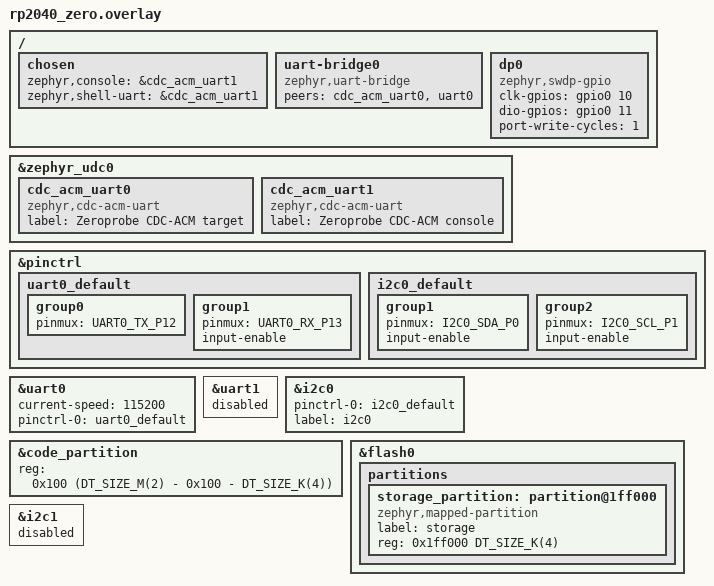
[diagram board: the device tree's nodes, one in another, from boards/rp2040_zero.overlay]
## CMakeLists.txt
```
# Copyright (c) 2023 Nordic Semiconductor ASA
# SPDX-License-Identifier: Apache-2.0
set(BOARD "rp2040_zero/rp2040")

cmake_minimum_required(VERSION 3.20.0)
find_package(Zephyr REQUIRED HINTS $ENV{ZEPHYR_BASE})
project(dap)

#include(${ZEPHYR_BASE}/samples/subsys/usb/common/common.cmake)
include_directories(include)
FILE(GLOB app_sources src/*.c)
target_sources(app PRIVATE ${app_sources})
# Hook USB transfer completions to drive the activity LED
target_link_options(app PUBLIC -Wl,--wrap=usbd_class_handle_xfer)
```

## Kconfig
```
# Copyright (c) 2026 Iacopo Moles
# SPDX-License-Identifier: Apache-2.0

menu "Zeroprobe options"
	depends on USB_DEVICE_STACK_NEXT

config APP_USBD_MANUFACTURER
	string "USB device sample manufacturer string"
	default "Zephyr Project"
	help
	  USB device sample manufacturer string.

config APP_USBD_PRODUCT
	string "USB device sample product string"
	default "Zeroprobe"
	help
	  USB device sample product stringa.

config APP_USBD_VID
	hex "USB device sample Vendor ID"
	default 0x2fe3
	help
	  USB device sample Vendor ID. The default id (0x2fe3) is associated to
	  Zephyr Project, you must use your own VID for samples and applications
	  outside of Zephyr Project.

config APP_USBD_PID
	hex "USB device sample Product ID"
	default 0x2ef0
	help
	  USB device sample Product ID. You must use your own PID for samples
	  and applications outside of Zephyr Project.

config APP_USBD_SELF_POWERED
	bool "USB device sample Self-powered attribute"
	default n
	help
	  Set the Self-powered attribute in the sample configuration.

config APP_USBD_REMOTE_WAKEUP
	bool "USB device sample Remote Wakeup attribute"
	help
	  Set the Remote Wakeup attribute in the sample configuration.

config APP_USBD_MAX_POWER
	int "USB device sample bMaxPower value"
	default 125
	range 0 250
	help
	  bMaxPower value in the sample configuration in 2 mA units.

config APP_USBD_20_EXTENSION_DESC
	bool "Use default USB 2.0 Extension Descriptor"
	depends on USBD_BOS_SUPPORT
	help
	  Set bcdUSB value to 0201 and use default USB 2.0 Extension Descriptor.

endmenu

menu "Zeroprobe status LED"

config APP_LED_COLOR_UNCONFIGURED
	hex "LED color when not configured by a USB host"
	default 0x200000
	range 0x000000 0xffffff
	help
	  Status LED color as 0xRRGGBB, shown at boot, after a USB bus reset,
	  or when the host deconfigures the device.

config APP_LED_COLOR_CONFIGURED
	hex "LED color when configured by a USB host"
	default 0x000020
	range 0x000000 0xffffff
	help
	  Status LED color as 0xRRGGBB, shown when the host has configured the
	  device and there is no USB traffic.

config APP_LED_COLOR_ACTIVE
	hex "LED color on USB traffic"
	default 0x002000
	range 0x000000 0xffffff
	help
	  Status LED color as 0xRRGGBB, shown while there is USB traffic on
	  any non-control endpoint.

config APP_LED_IDLE_TIMEOUT_MS
	int "USB traffic idle timeout in milliseconds"
	default 500
	range 1 60000
	help
	  Time without USB traffic before the status LED falls back from the
	  active color to the configured color.

endmenu


source "Kconfig.zephyr"
```

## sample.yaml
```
# This file is provided so that the application can be compiled using Twister,
# the Zephyr testing tool. In this file, multiple combinations can be specified,
# so that you can easily test all of them locally or in CI.
sample:
  description: Example application
  name: example-application 
common:
  build_only: true
  integration_platforms:
    - rp2040_zero
tests:
  app.default: {}
  app.debug:
    extra_overlay_confs:
      - debug.conf
```

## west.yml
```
manifest:
  remotes:
    - name: zephyrproject
      url-base: https://github.com/zephyrproject-rtos
  projects:
    - name: zephyr
      repo-path: zephyr
      remote: zephyrproject
      revision: "v4.5.0-rc3"
      clone-depth: 1
      import:
        path-prefix: external
        name-allowlist:
          - cmsis_6
          - hal_rpi_pico
```

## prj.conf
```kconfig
CONFIG_USB_DEVICE_STACK_NEXT=y
# CMSIS-DAP commands and SWD transfers run in the USB device stack thread
CONFIG_USBD_THREAD_STACK_SIZE=2048
CONFIG_UDC_RPI_PICO_STACK_SIZE=1024
CONFIG_CDC_ACM_SERIAL_INITIALIZE_AT_BOOT=n
CONFIG_APP_USBD_PRODUCT="Zeroprobe CMSIS-DAP"
CONFIG_APP_USBD_PID=0x2ef0
CONFIG_APP_USBD_20_EXTENSION_DESC=y
CONFIG_APP_USBD_SELF_POWERED=n

CONFIG_STDOUT_CONSOLE=y
CONFIG_SERIAL=y
CONFIG_UART_INTERRUPT_DRIVEN=y
CONFIG_UART_LINE_CTRL=y

CONFIG_LOG=y
CONFIG_LOG_DEFAULT_LEVEL=2

CONFIG_DAP_LOG_LEVEL_INF=y
CONFIG_DP_DRIVER_LOG_LEVEL_INF=y
CONFIG_DAP=y
CONFIG_DAP_BACKEND_USB=y
CONFIG_CMSIS_DAP_PROBE_VENDOR="Zephyr"
CONFIG_CMSIS_DAP_PROBE_NAME="CMSIS-DAP"
CONFIG_CMSIS_DAP_BOARD_VENDOR="Waveshare"
CONFIG_CMSIS_DAP_BOARD_NAME="RP2040-Zero"
# Leave empty: the probe is not tied to a target, and pyOCD/OpenOCD would
# otherwise try to use the device name as the target type
CONFIG_CMSIS_DAP_DEVICE_VENDOR=""
CONFIG_CMSIS_DAP_DEVICE_NAME=""

CONFIG_GPIO=y
CONFIG_LED_STRIP=y
# Status LED colors stored in the storage partition
CONFIG_FLASH=y
CONFIG_FLASH_MAP=y
CONFIG_CRC=y
CONFIG_I2C=y
CONFIG_SHELL=y
CONFIG_SHELL_STACK_SIZE=3072
CONFIG_I2C_SHELL=y

CONFIG_DEVICE_SHELL=y
CONFIG_DEVICE_SHELL_INIT_CMD=y
CONFIG_DATE_SHELL=n
CONFIG_DEVMEM_SHELL=n
CONFIG_APP_VERSION_SHELL=y
CONFIG_SHELL_MINIMAL=n
CONFIG_STATS=n

CONFIG_SPEED_OPTIMIZATIONS=y
CONFIG_BUILD_OUTPUT_STRIPPED=y
```

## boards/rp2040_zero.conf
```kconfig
CONFIG_USBD_CDC_ACM_LOG_LEVEL_OFF=y

# Status LED colors as 0xRRGGBB, keep values low, the WS2812 is very bright
CONFIG_APP_LED_COLOR_UNCONFIGURED=0x200000
CONFIG_APP_LED_COLOR_CONFIGURED=0x000020
CONFIG_APP_LED_COLOR_ACTIVE=0x002000
CONFIG_APP_LED_IDLE_TIMEOUT_MS=500

# RPI PICO binary info, shown by 'picotool info -a'.
CONFIG_RPI_PICO_BINARY_INFO=y
CONFIG_RPI_PICO_BINARY_INFO_OVERRIDE_PROGRAM_NAME="Zeroprobe"
CONFIG_RPI_PICO_BINARY_INFO_OVERRIDE_PROGRAM_DESCRIPTION="CMSIS-DAP debug probe for the Waveshare RP2040-Zero"
CONFIG_RPI_PICO_BINARY_INFO_OVERRIDE_PROGRAM_URL="https://github.com/icpmoles/zeroprobe"
CONFIG_RPI_PICO_BINARY_INFO_PROGRAM_VERSION_STRING=y
CONFIG_RPI_PICO_BINARY_INFO_PIN_CONFIGURATIONS=y
```

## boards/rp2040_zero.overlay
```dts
/ {
	chosen {
		zephyr,console = &cdc_acm_uart1;
		zephyr,shell-uart = &cdc_acm_uart1;
	};

	uart-bridge0 {
		compatible = "zephyr,uart-bridge";
		peers = <&cdc_acm_uart0 &uart0>;
	};

	dp0 {
		compatible = "zephyr,swdp-gpio";
		status = "okay";
		clk-gpios = <&gpio0 10 GPIO_ACTIVE_HIGH>;
		dio-gpios = <&gpio0 11 GPIO_PULL_UP>;
		port-write-cycles = <1>;
	};
};

&zephyr_udc0 {
	cdc_acm_uart0: cdc_acm_uart0 {
		compatible = "zephyr,cdc-acm-uart";
		label = "Zeroprobe CDC-ACM target";
	};

	cdc_acm_uart1: cdc_acm_uart1 {
		compatible = "zephyr,cdc-acm-uart";
		label = "Zeroprobe CDC-ACM console";
	};
};

&pinctrl {
	uart0_default: uart0_default {
		group0 {
			pinmux = <UART0_TX_P12>;
		};

		group1 {
			pinmux = <UART0_RX_P13>;
			input-enable;
		};
	};

	i2c0_default: i2c0_default {
		group1 {
			pinmux = <I2C0_SDA_P0>;
			input-enable;
		};

		group2 {
			pinmux = <I2C0_SCL_P1>;
			input-enable;
		};
	};

};

&uart0 {
	current-speed = <115200>;
	pinctrl-names = "default";
	status = "okay";
	pinctrl-0 = <&uart0_default>;
};

&uart1 {
	status = "disabled";
};

&i2c0 {
	pinctrl-0 = <&i2c0_default>;
	label = "i2c0";
};

/* Take the last flash sector from the code partition for persistent data */
&code_partition {
	reg = <0x100 (DT_SIZE_M(2) - 0x100 - DT_SIZE_K(4))>;
};

&flash0 {
	partitions {
		storage_partition: partition@1ff000 {
			compatible = "zephyr,mapped-partition";
			label = "storage";
			reg = <0x1ff000 DT_SIZE_K(4)>;
		};
	};
};

&i2c1 {
	status = "disabled";
};
```

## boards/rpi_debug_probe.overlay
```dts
/*
 * Copyright The Zephyr Project Contributors
 *
 * SPDX-License-Identifier: Apache-2.0
 */

/ {
	chosen {
		zephyr,console = &cdc_acm_uart1;
		zephyr,shell-uart = &cdc_acm_uart1;
	};

	uart-bridge0 {
		compatible = "zephyr,uart-bridge";
		peers = <&cdc_acm_uart0 &uart0>;
	};

	dp0 {
		compatible = "zephyr,swdp-gpio";
		status = "okay";
		clk-gpios = <&gpio0 10 GPIO_ACTIVE_HIGH>;
		dio-gpios = <&gpio0 11 GPIO_PULL_UP>;
		port-write-cycles = <1>;
	};
};

&zephyr_udc0 {
	cdc_acm_uart0: cdc_acm_uart0 {
		compatible = "zephyr,cdc-acm-uart";
		label = "Zephyr USB CDC-ACM target";
	};

	cdc_acm_uart1: cdc_acm_uart1 {
		compatible = "zephyr,cdc-acm-uart";
		label = "Zephyr USB CDC-ACM console";
	};
};

&pinctrl {
	uart0_default: uart0_default {
		group0 {
			pinmux = <UART0_TX_P12>;
		};

		group1 {
			pinmux = <UART0_RX_P13>;
			input-enable;
		};
	};
};

&uart0 {
	current-speed = <115200>;
	pinctrl-names = "default";
	status = "okay";
	pinctrl-0 = <&uart0_default>;
};
&uart1 {
	status = "disabled";
};
```

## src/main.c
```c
/*
 * Copyright (c) 2023 Nordic Semiconductor ASA
 * Copyright (c) 2026 Iacopo Moles
 *
 * SPDX-License-Identifier: Apache-2.0
 */

#include "usbd_impl.h"
#include "status_led.h"

#include <zephyr/kernel.h>
#include <zephyr/device.h>
#include <zephyr/sys/byteorder.h>
#include <zephyr/usb/usbd.h>
#include <zephyr/usb/bos.h>
#include <zephyr/usb/msos_desc.h>
#include <zephyr/dap/dap_link.h>
#include <zephyr/drivers/uart/uart_bridge.h>

#include <zephyr/logging/log.h>
LOG_MODULE_REGISTER(dap_sample, LOG_LEVEL_INF);

#include "webusb.h"
#include "msosv2.h"

DAP_LINK_CONTEXT_DEFINE(sample_dap_ctx, DEVICE_DT_GET_ONE(zephyr_swdp_gpio));

/* Bridges the target CDC ACM port and the target UART */
static const struct device *const uart_bridge = DEVICE_DT_GET_ONE(zephyr_uart_bridge);

/*
 * The USB device stack has no traffic notification, so intercept the
 * dispatch of completed non-control endpoint transfers to class instances.
 * Wrapped with -Wl,--wrap=usbd_class_handle_xfer, see CMakeLists.txt.
 */
int __real_usbd_class_handle_xfer(struct usbd_context *const uds_ctx,
				  struct net_buf *const buf,
				  const int err);

int __wrap_usbd_class_handle_xfer(struct usbd_context *const uds_ctx,
				  struct net_buf *const buf,
				  const int err)
{
	if (err == 0) {
		status_led_activity();
	}

	return __real_usbd_class_handle_xfer(uds_ctx, buf, err);
}

static void sample_msg_cb(struct usbd_context *const ctx, const struct usbd_msg *msg)
{
	// LOG_INF("USBD message: %s", usbd_msg_type_string(msg->type));

	/*
	 * Unconfigured, configured by the host, or active on traffic within the
	 * idle timeout, colors and timeout are set from the 'led' shell command.
	 * Other messages, e.g. CDC ACM line state, leave the LED unchanged.
	 */
	switch (msg->type) {
	case USBD_MSG_RESET:
	case USBD_MSG_VBUS_REMOVED:
		status_led_set(STATUS_LED_UNCONFIGURED);
		break;
	case USBD_MSG_CONFIGURATION:
		/* Status is the configuration value, 0 means unconfigured */
		status_led_set(msg->status ? STATUS_LED_CONFIGURED : STATUS_LED_UNCONFIGURED);
		break;
	default:
		break;
	}

	if (usbd_can_detect_vbus(ctx)) {
		if (msg->type == USBD_MSG_VBUS_READY) {
			if (usbd_enable(ctx)) {
				LOG_ERR("Failed to enable device support");
			}
		}

		if (msg->type == USBD_MSG_VBUS_REMOVED) {
			if (usbd_disable(ctx)) {
				LOG_ERR("Failed to disable device support");
			}
		}
	}

	/*
	 * Apply the baud rate and framing chosen on the host to the target UART,
	 * the bridge does not do it on its own. Ports that are not part of the
	 * bridge, e.g. the console, are skipped.
	 */
	if (msg->type == USBD_MSG_CDC_ACM_LINE_CODING ||
	    msg->type == USBD_MSG_CDC_ACM_CONTROL_LINE_STATE) {
		uart_bridge_settings_update(msg->dev, uart_bridge);
	}
}

int main(void)
{
	struct usbd_context *usbd_device;
	int ret;

	ret = status_led_init();
	if (ret) {
		return ret;
	}

	ret = dap_link_init(&sample_dap_ctx);
	if (ret) {
		LOG_ERR("Failed to initialize DAP controller, %d", ret);
		return ret;
	}

	ret = dap_link_backend_usb_init(&sample_dap_ctx);
	if (ret) {
		LOG_ERR("Failed to initialize DAP Link USB backend, %d", ret);
		return ret;
	}

	usbd_device = usbd_setup_device(sample_msg_cb);
	if (usbd_device == NULL) {
		LOG_ERR("Failed to setup USB device");
		return -ENODEV;
	}

	ret = usbd_add_descriptor(usbd_device, &bos_vreq_msosv2);
	if (ret) {
		LOG_ERR("Failed to add MSOSv2 capability descriptor");
		return ret;
	}

	ret = usbd_add_descriptor(usbd_device, &bos_vreq_webusb);
	if (ret) {
		LOG_ERR("Failed to add WebUSB capability descriptor");
		return ret;
	}

	ret = usbd_init(usbd_device);
	if (ret) {
		LOG_ERR("Failed to initialize device support");
		return ret;
	}

	if (!usbd_can_detect_vbus(usbd_device)) {
		ret = usbd_enable(usbd_device);
		if (ret) {
			LOG_ERR("Failed to enable device support");
			return ret;
		}
	}

	return 0;
}
```

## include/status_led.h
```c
/*
 * Copyright (c) 2026 Iacopo Moles
 *
 * SPDX-License-Identifier: Apache-2.0
 */

#ifndef ZEROPROBE_STATUS_LED_H
#define ZEROPROBE_STATUS_LED_H

enum status_led_state {
	/* Not configured by a USB host */
	STATUS_LED_UNCONFIGURED,
	/* Configured by the host, no USB traffic */
	STATUS_LED_CONFIGURED,
	/* USB traffic within the idle timeout, see 'led timeout' */
	STATUS_LED_ACTIVE,
	STATUS_LED_STATE_COUNT,
};

/*
 * Load the colors and idle timeout stored in the storage partition, falling
 * back to the Kconfig defaults, and show the unconfigured color.
 */
int status_led_init(void);

void status_led_set(enum status_led_state state);

/* Show the active color, and fall back to configured once traffic stops */
void status_led_activity(void);

#endif /* ZEROPROBE_STATUS_LED_H */
```

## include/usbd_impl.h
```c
//
// Created by icpmoles on 4/26/26.
//


#ifndef ZEPHYR_SAMPLES_SUBSYS_USB_COMMON_USBD_H
#define ZEPHYR_SAMPLES_SUBSYS_USB_COMMON_USBD_H

#include <stdint.h>
#include <zephyr/usb/usbd.h>

/*
 * The scope of this header is limited to use in USB samples together with the
 * new experimental USB device stack, you should not use it in your own
 * application. However, you can use the code as a template.
 */

/*
 * This function uses Kconfig.sample_usbd options to configure and initialize a
 * USB device. It configures sample's device context, default string descriptors,
 * USB device configuration, registers any available class instances, and
 * finally initializes USB device. It is limited to a single device with a
 * single configuration instantiated in sample_usbd_init.c, which should be
 * enough for a simple USB device sample.
 *
 * It returns the configured and initialized USB device context on success,
 * otherwise it returns NULL.
 */
struct usbd_context *usbd_init_device(usbd_msg_cb_t msg_cb);

/*
 * This function is similar to sample_usbd_init_device(), but does not
 * initialize the device. It allows the application to set additional features,
 * such as additional descriptors.
 */
struct usbd_context *usbd_setup_device(usbd_msg_cb_t msg_cb);

#endif //#define ZEPHYR_SAMPLES_SUBSYS_USB_COMMON_USBD_H
```

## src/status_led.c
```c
/*
 * Copyright (c) 2026 Iacopo Moles
 *
 * SPDX-License-Identifier: Apache-2.0
 */

#include "status_led.h"

#include <stddef.h>
#include <string.h>

#include <zephyr/kernel.h>
#include <zephyr/device.h>
#include <zephyr/drivers/led_strip.h>
#include <zephyr/shell/shell.h>
#include <zephyr/storage/flash_map.h>
#include <zephyr/sys/crc.h>

#include <zephyr/logging/log.h>
LOG_MODULE_REGISTER(status_led, LOG_LEVEL_INF);

#define LED_STORAGE_ID PARTITION_ID(storage_partition)

/* Bump when the layout of struct led_settings changes */
#define LED_SETTINGS_MAGIC 0x324c505aU /* "ZPL2" */

#define LED_COLOR_MAX 0xffffffU

/* Same range as CONFIG_APP_LED_IDLE_TIMEOUT_MS */
#define LED_TIMEOUT_MIN_MS 1U
#define LED_TIMEOUT_MAX_MS 60000U

/*
 * Fixed record at the start of the storage partition, read with a single
 * flash_area_read() at boot. Erased flash reads as 0xff and fails the magic
 * check, a torn write fails the CRC check.
 */
struct led_settings {
	uint32_t magic;
	/* 0xRRGGBB, indexed by enum status_led_state */
	uint32_t colors[STATUS_LED_STATE_COUNT];
	/* Time without USB traffic before falling back from active to configured */
	uint32_t idle_timeout_ms;
	/* CRC32 (IEEE) of all the fields above */
	uint32_t crc;
};

static const struct led_settings led_defaults = {
	.colors = {
		[STATUS_LED_UNCONFIGURED] = CONFIG_APP_LED_COLOR_UNCONFIGURED,
		[STATUS_LED_CONFIGURED] = CONFIG_APP_LED_COLOR_CONFIGURED,
		[STATUS_LED_ACTIVE] = CONFIG_APP_LED_COLOR_ACTIVE,
	},
	.idle_timeout_ms = CONFIG_APP_LED_IDLE_TIMEOUT_MS,
};

static const char *const led_state_names[STATUS_LED_STATE_COUNT] = {
	[STATUS_LED_UNCONFIGURED] = "unconfigured",
	[STATUS_LED_CONFIGURED] = "configured",
	[STATUS_LED_ACTIVE] = "active",
};

static const struct device *const led_strip = DEVICE_DT_GET(DT_ALIAS(led_strip));

/* Updated from main, the USB stack thread, the system work queue and the shell */
static K_MUTEX_DEFINE(led_lock);
static uint32_t led_colors[STATUS_LED_STATE_COUNT];
/* Read without led_lock for every USB transfer, a 32-bit load is atomic */
static uint32_t led_idle_timeout_ms;
static enum status_led_state led_state = STATUS_LED_STATE_COUNT;

/* Must be called with led_lock held */
static void led_show(enum status_led_state state, bool force)
{
	struct led_rgb pixel = {
		.r = (led_colors[state] >> 16) & 0xff,
		.g = (led_colors[state] >> 8) & 0xff,
		.b = led_colors[state] & 0xff,
	};
	int ret;

	/* Skip redundant updates, this is called for every USB transfer */
	if (state == led_state && !force) {
		return;
	}

	ret = led_strip_update_rgb(led_strip, &pixel, 1);
	if (ret) {
		LOG_ERR("Failed to update LED strip, %d", ret);
		return;
	}

	led_state = state;
}

void status_led_set(enum status_led_state state)
{
	k_mutex_lock(&led_lock, K_FOREVER);
	led_show(state, false);
	k_mutex_unlock(&led_lock);
}

static void led_idle_handler(struct k_work *work)
{
	ARG_UNUSED(work);

	/* Fall back from active to configured, unless the device was reset
	 * or unconfigured in the meantime
	 */
	k_mutex_lock(&led_lock, K_FOREVER);
	if (led_state == STATUS_LED_ACTIVE) {
		led_show(STATUS_LED_CONFIGURED, false);
	}
	k_mutex_unlock(&led_lock);
}

static K_WORK_DELAYABLE_DEFINE(led_idle_work, led_idle_handler);

void status_led_activity(void)
{
	status_led_set(STATUS_LED_ACTIVE);
	k_work_reschedule(&led_idle_work, K_MSEC(led_idle_timeout_ms));
}

static uint32_t led_settings_crc(const struct led_settings *settings)
{
	return crc32_ieee((const uint8_t *)settings, offsetof(struct led_settings, crc));
}

/* Returns 0 and fills settings if a valid record is stored */
static int led_settings_load(struct led_settings *settings)
{
	const struct flash_area *fa;
	int ret;

	ret = flash_area_open(LED_STORAGE_ID, &fa);
	if (ret) {
		return ret;
	}

	ret = flash_area_read(fa, 0, settings, sizeof(*settings));
	flash_area_close(fa);
	if (ret) {
		return ret;
	}

	if (settings->magic != LED_SETTINGS_MAGIC ||
	    settings->crc != led_settings_crc(settings)) {
		return -ENOENT;
	}

	for (int i = 0; i < STATUS_LED_STATE_COUNT; i++) {
		if (settings->colors[i] > LED_COLOR_MAX) {
			return -EINVAL;
		}
	}

	if (settings->idle_timeout_ms < LED_TIMEOUT_MIN_MS ||
	    settings->idle_timeout_ms > LED_TIMEOUT_MAX_MS) {
		return -EINVAL;
	}

	return 0;
}

static int led_settings_save(struct led_settings *settings)
{
	const struct flash_area *fa;
	int ret;

	settings->magic = LED_SETTINGS_MAGIC;
	settings->crc = led_settings_crc(settings);

	ret = flash_area_open(LED_STORAGE_ID, &fa);
	if (ret) {
		return ret;
	}

	ret = flash_area_erase(fa, 0, fa->fa_size);
	if (ret == 0) {
		ret = flash_area_write(fa, 0, settings, sizeof(*settings));
	}

	flash_area_close(fa);

	return ret;
}

static int led_settings_erase(void)
{
	const struct flash_area *fa;
	int ret;

	ret = flash_area_open(LED_STORAGE_ID, &fa);
	if (ret) {
		return ret;
	}

	ret = flash_area_erase(fa, 0, fa->fa_size);
	flash_area_close(fa);

	return ret;
}

/* Must be called with led_lock held */
static void led_apply_settings(const struct led_settings *settings)
{
	memcpy(led_colors, settings->colors, sizeof(led_colors));
	led_idle_timeout_ms = settings->idle_timeout_ms;
}

int status_led_init(void)
{
	struct led_settings settings;
	int ret;

	if (!device_is_ready(led_strip)) {
		LOG_ERR("LED strip device %s is not ready", led_strip->name);
		return -ENODEV;
	}

	k_mutex_lock(&led_lock, K_FOREVER);

	ret = led_settings_load(&settings);
	if (ret) {
		LOG_DBG("No stored LED settings (%d), using defaults", ret);
		led_apply_settings(&led_defaults);
	} else {
		led_apply_settings(&settings);
	}

	led_show(STATUS_LED_UNCONFIGURED, true);

	k_mutex_unlock(&led_lock);

	return 0;
}

static int cmd_led_show(const struct shell *sh, size_t argc, char **argv)
{
	ARG_UNUSED(argc);
	ARG_UNUSED(argv);

	k_mutex_lock(&led_lock, K_FOREVER);
	for (int i = 0; i < STATUS_LED_STATE_COUNT; i++) {
		shell_print(sh, "%-12s 0x%06x%s", led_state_names[i], led_colors[i],
			    i == led_state ? " (current)" : "");
	}
	shell_print(sh, "%-12s %u ms", "timeout", led_idle_timeout_ms);
	k_mutex_unlock(&led_lock);

	return 0;
}

static int cmd_led_set(const struct shell *sh, size_t argc, char **argv)
{
	unsigned long color;
	int state;
	int err = 0;

	ARG_UNUSED(argc);

	for (state = 0; state < STATUS_LED_STATE_COUNT; state++) {
		if (strcmp(argv[1], led_state_names[state]) == 0) {
			break;
		}
	}

	if (state == STATUS_LED_STATE_COUNT) {
		shell_error(sh, "Unknown state %s, use unconfigured, configured or active",
			    argv[1]);
		return -EINVAL;
	}

	color = shell_strtoul(argv[2], 16, &err);
	if (err || color > LED_COLOR_MAX) {
		shell_error(sh, "Invalid color %s, use RRGGBB, e.g. 0x002000", argv[2]);
		return -EINVAL;
	}

	k_mutex_lock(&led_lock, K_FOREVER);
	led_colors[state] = color;
	if (state == led_state) {
		led_show(state, true);
	}
	k_mutex_unlock(&led_lock);

	shell_print(sh, "%s set to 0x%06lx, run 'led save' to keep it after a reboot",
		    led_state_names[state], color);

	return 0;
}

static int cmd_led_timeout(const struct shell *sh, size_t argc, char **argv)
{
	unsigned long timeout;
	int err = 0;

	if (argc < 2) {
		shell_print(sh, "%u ms", led_idle_timeout_ms);
		return 0;
	}

	timeout = shell_strtoul(argv[1], 10, &err);
	if (err || timeout < LED_TIMEOUT_MIN_MS || timeout > LED_TIMEOUT_MAX_MS) {
		shell_error(sh, "Invalid timeout %s, use %u to %u ms", argv[1],
			    LED_TIMEOUT_MIN_MS, LED_TIMEOUT_MAX_MS);
		return -EINVAL;
	}

	k_mutex_lock(&led_lock, K_FOREVER);
	led_idle_timeout_ms = timeout;
	k_mutex_unlock(&led_lock);

	shell_print(sh, "Idle timeout set to %lu ms, run 'led save' to keep it after a reboot",
		    timeout);

	return 0;
}

static int cmd_led_save(const struct shell *sh, size_t argc, char **argv)
{
	struct led_settings settings;
	int ret;

	ARG_UNUSED(argc);
	ARG_UNUSED(argv);

	k_mutex_lock(&led_lock, K_FOREVER);
	memcpy(settings.colors, led_colors, sizeof(settings.colors));
	settings.idle_timeout_ms = led_idle_timeout_ms;
	k_mutex_unlock(&led_lock);

	ret = led_settings_save(&settings);
	if (ret) {
		shell_error(sh, "Failed to save LED settings, %d", ret);
		return ret;
	}

	shell_print(sh, "LED settings saved");

	return 0;
}

static int cmd_led_reset(const struct shell *sh, size_t argc, char **argv)
{
	int ret;

	ARG_UNUSED(argc);
	ARG_UNUSED(argv);

	ret = led_settings_erase();
	if (ret) {
		shell_error(sh, "Failed to erase stored LED settings, %d", ret);
		return ret;
	}

	k_mutex_lock(&led_lock, K_FOREVER);
	led_apply_settings(&led_defaults);
	if (led_state < STATUS_LED_STATE_COUNT) {
		led_show(led_state, true);
	}
	k_mutex_unlock(&led_lock);

	shell_print(sh, "LED settings reset to the defaults");

	return 0;
}

SHELL_STATIC_SUBCMD_SET_CREATE(sub_led,
	SHELL_CMD(show, NULL, "Show the status LED settings", cmd_led_show),
	SHELL_CMD_ARG(set, NULL,
		      "Set a status LED color, until reboot unless saved\n"
		      "Usage: led set <unconfigured|configured|active> <RRGGBB>",
		      cmd_led_set, 3, 0),
	SHELL_CMD_ARG(timeout, NULL,
		      "Show or set the USB traffic idle timeout, until reboot unless saved\n"
		      "Usage: led timeout [ms]",
		      cmd_led_timeout, 1, 1),
	SHELL_CMD(save, NULL, "Save the status LED settings to flash", cmd_led_save),
	SHELL_CMD(reset, NULL, "Erase the saved settings and use the defaults", cmd_led_reset),
	SHELL_SUBCMD_SET_END);

SHELL_CMD_REGISTER(led, &sub_led, "Status LED settings", NULL);
```

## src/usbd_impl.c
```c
/*
 * Copyright (c) 2023 Nordic Semiconductor ASA
 *
 * SPDX-License-Identifier: Apache-2.0
 */

#include <stdint.h>

#include <zephyr/device.h>
#include <zephyr/usb/usbd.h>
#include <zephyr/usb/bos.h>

#include <zephyr/logging/log.h>
LOG_MODULE_REGISTER(usbd_config);

/* By default, do not register the USB DFU class DFU mode instance. */
static const char *const blocklist[] = {
	"dfu_dfu",
	NULL,
};

/* doc device instantiation start */
/*
 * Instantiate a context named sample_usbd using the default USB device
 * controller, the Zephyr project vendor ID, and the sample product ID.
 * Zephyr project vendor ID must not be used outside of Zephyr samples.
 */
USBD_DEVICE_DEFINE(sample_usbd,
		   DEVICE_DT_GET(DT_NODELABEL(zephyr_udc0)),
		   CONFIG_APP_USBD_VID, CONFIG_APP_USBD_PID);
/* doc device instantiation end */

/* doc string instantiation start */
USBD_DESC_LANG_DEFINE(sample_lang);
USBD_DESC_MANUFACTURER_DEFINE(sample_mfr, CONFIG_APP_USBD_MANUFACTURER);
USBD_DESC_PRODUCT_DEFINE(sample_product, CONFIG_APP_USBD_PRODUCT);
IF_ENABLED(CONFIG_HWINFO, (USBD_DESC_SERIAL_NUMBER_DEFINE(sample_sn)));

/* doc string instantiation end */

USBD_DESC_CONFIG_DEFINE(fs_cfg_desc, "FS Configuration");
USBD_DESC_CONFIG_DEFINE(hs_cfg_desc, "HS Configuration");

/* doc configuration instantiation start */
static const uint8_t attributes = (IS_ENABLED(CONFIG_APP_USBD_SELF_POWERED) ?
				   USB_SCD_SELF_POWERED : 0) |
				  (IS_ENABLED(CONFIG_APP_USBD_REMOTE_WAKEUP) ?
				   USB_SCD_REMOTE_WAKEUP : 0);

/* Full speed configuration */
USBD_CONFIGURATION_DEFINE(sample_fs_config,
			  attributes,
			  CONFIG_APP_USBD_MAX_POWER, &fs_cfg_desc);

/* High speed configuration */
USBD_CONFIGURATION_DEFINE(sample_hs_config,
			  attributes,
			  CONFIG_APP_USBD_MAX_POWER, &hs_cfg_desc);
/* doc configuration instantiation end */

#if CONFIG_APP_USBD_20_EXTENSION_DESC
/*
 * This does not yet provide valuable information, but rather serves as an
 * example, and will be improved in the future.
 */
static const struct usb_bos_capability_lpm bos_cap_lpm = {
	.bLength = sizeof(struct usb_bos_capability_lpm),
	.bDescriptorType = USB_DESC_DEVICE_CAPABILITY,
	.bDevCapabilityType = USB_BOS_CAPABILITY_EXTENSION,
	.bmAttributes = 0UL,
};

USBD_DESC_BOS_DEFINE(sample_usbext, sizeof(bos_cap_lpm), &bos_cap_lpm);
#endif

static void sample_fix_code_triple(struct usbd_context *uds_ctx,
				   const enum usbd_speed speed)
{
	/* Always use class code information from Interface Descriptors */
	if (IS_ENABLED(CONFIG_USBD_CDC_ACM_CLASS) ||
	    IS_ENABLED(CONFIG_USBD_CDC_ECM_CLASS) ||
	    IS_ENABLED(CONFIG_USBD_CDC_NCM_CLASS) ||
	    IS_ENABLED(CONFIG_USBD_MIDI2_CLASS) ||
	    IS_ENABLED(CONFIG_USBD_AUDIO2_CLASS) ||
	    IS_ENABLED(CONFIG_USBD_VIDEO_CLASS)) {
		/*
		 * Class with multiple interfaces have an Interface
		 * Association Descriptor available, use an appropriate triple
		 * to indicate it.
		 */
		usbd_device_set_code_triple(uds_ctx, speed,
					    USB_BCC_MISCELLANEOUS, 0x02, 0x01);
	} else {
		usbd_device_set_code_triple(uds_ctx, speed, 0, 0, 0);
	}
}

struct usbd_context *usbd_setup_device(usbd_msg_cb_t msg_cb)
{
	int err;

	/* doc add string descriptor start */
	err = usbd_add_descriptor(&sample_usbd, &sample_lang);
	if (err) {
		LOG_ERR("Failed to initialize language descriptor (%d)", err);
		return NULL;
	}

	err = usbd_add_descriptor(&sample_usbd, &sample_mfr);
	if (err) {
		LOG_ERR("Failed to initialize manufacturer descriptor (%d)", err);
		return NULL;
	}

	err = usbd_add_descriptor(&sample_usbd, &sample_product);
	if (err) {
		LOG_ERR("Failed to initialize product descriptor (%d)", err);
		return NULL;
	}

	IF_ENABLED(CONFIG_HWINFO, (
		err = usbd_add_descriptor(&sample_usbd, &sample_sn);
	))
	if (err) {
		LOG_ERR("Failed to initialize SN descriptor (%d)", err);
		return NULL;
	}
	/* doc add string descriptor end */

	if (USBD_SUPPORTS_HIGH_SPEED &&
	    usbd_caps_speed(&sample_usbd) == USBD_SPEED_HS) {
		err = usbd_add_configuration(&sample_usbd, USBD_SPEED_HS,
					     &sample_hs_config);
		if (err) {
			LOG_ERR("Failed to add High-Speed configuration");
			return NULL;
		}

		err = usbd_register_all_classes(&sample_usbd, USBD_SPEED_HS, 1,
						blocklist);
		if (err) {
			LOG_ERR("Failed to add register classes");
			return NULL;
		}

		sample_fix_code_triple(&sample_usbd, USBD_SPEED_HS);
	}

	/* doc configuration register start */
	err = usbd_add_configuration(&sample_usbd, USBD_SPEED_FS,
				     &sample_fs_config);
	if (err) {
		LOG_ERR("Failed to add Full-Speed configuration");
		return NULL;
	}
	/* doc configuration register end */

	/* doc functions register start */
	err = usbd_register_all_classes(&sample_usbd, USBD_SPEED_FS, 1, blocklist);
	if (err) {
		LOG_ERR("Failed to add register classes");
		return NULL;
	}
	/* doc functions register end */

	sample_fix_code_triple(&sample_usbd, USBD_SPEED_FS);
	usbd_self_powered(&sample_usbd, attributes & USB_SCD_SELF_POWERED);

	if (msg_cb != NULL) {
		/* doc device init-and-msg start */
		err = usbd_msg_register_cb(&sample_usbd, msg_cb);
		if (err) {
			LOG_ERR("Failed to register message callback");
			return NULL;
		}
		/* doc device init-and-msg end */
	}

#if CONFIG_APP_USBD_20_EXTENSION_DESC
	(void)usbd_device_set_bcd_usb(&sample_usbd, USBD_SPEED_FS, 0x0201);
	(void)usbd_device_set_bcd_usb(&sample_usbd, USBD_SPEED_HS, 0x0201);

	err = usbd_add_descriptor(&sample_usbd, &sample_usbext);
	if (err) {
		LOG_ERR("Failed to add USB 2.0 Extension Descriptor");
		return NULL;
	}
#endif

	return &sample_usbd;
}

struct usbd_context *usbd_init_device(usbd_msg_cb_t msg_cb)
{
	int err;

	if (usbd_setup_device(msg_cb) == NULL) {
		return NULL;
	}

	/* doc device init start */
	err = usbd_init(&sample_usbd);
	if (err) {
		LOG_ERR("Failed to initialize device support");
		return NULL;
	}
	/* doc device init end */

	return &sample_usbd;
}
```
